VERSION ""

NS_ :

BS_:
BU_: VCU
BO_ 513 Motor: 3 VCU
   SG_ motor_mode : 0|8@1+ (1,0) [0|1] "" Vector__XXX
   SG_ torque_value : 8|16@1- (1,0) [0|1] "" Vector__XXX

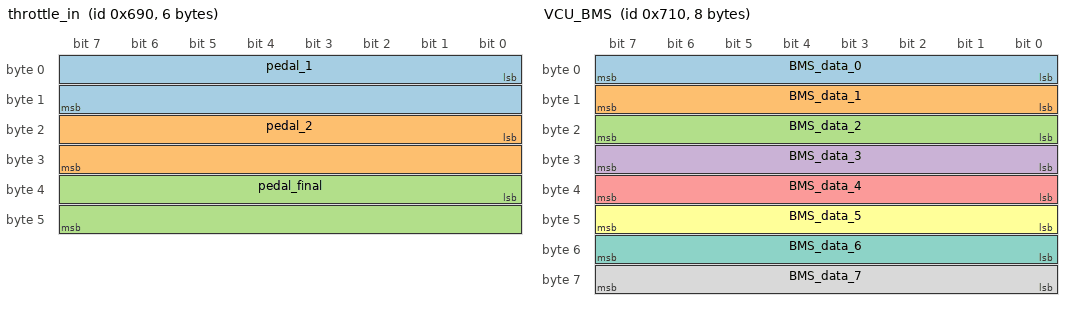
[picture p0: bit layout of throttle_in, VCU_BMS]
BO_ 1680 throttle_in: 6 VCU
   SG_ pedal_1 : 0|16@1+ (1,0) [0|1] "" Vector__XXX
   SG_ pedal_2 : 16|16@1+ (1,0) [0|1] "" Vector__XXX
   SG_ pedal_final : 32|16@1+ (1,0) [0|1] "" Vector__XXX

BO_ 1681 throttle_out: 6 VCU
   SG_ throttle_final : 0|16@1+ (1,0) [0|1] "" Vector__XXX
   SG_ throttle_torque_val : 16|16@1+ (1,0) [0|1] "" Vector__XXX

BO_ 1682 fault: 6 VCU
   SG_ fault_code : 0|8@1+ (1,0) [0|1] "" Vector__XXX
   SG_ delta : 8|32@5- (1,0) [0|1] "" Vector__XXX

BO_ 1683 car_status: 6 VCU
   SG_ car_status : 0|8@1+ (1,0) [0|1] "" Vector__XXX

BO_ 1792 TelemetryPedal: 8 VCU
   SG_ A01_APPS_5V : 0|10@1+ (1,0) [0|1] "" Vector__XXX
   SG_ A02_APPS_3V3 : 10|10@1+ (1,0) [0|1] "" Vector__XXX
   SG_ A03_BRAKE_IN : 20|10@1+ (1,0) [0|1] "" Vector__XXX
   SG_ A04_HALL_SENSOR : 30|10@1+ (1,0) [0|1] "" Vector__XXX
   SG_ B02_car_status_unknown : 42|1@0+ (1,0) [0|1] "" Vector__XXX
   SG_ B01_Car_state : 40|2@1+ (1,0) [0|3] "" Vector__XXX
   SG_ PedalFaultActive : 48|1@1+ (1,0) [0|255] "" Vector__XXX
   SG_ C00_Pedal_diff_fault_active : 48|1@1+ (1,0) [0|255] "" Vector__XXX
   SG_ B03_hv_on_ : 43|1@1+ (1,0) [0|1] "" Vector__XXX
   SG_ B04_read_no_message_ : 44|1@1+ (1,0) [0|1] "" Vector__XXX
   SG_ B05_read_wrong_id_ : 45|1@1+ (1,0) [0|1] "" Vector__XXX
   SG_ B06_throttle_break_ : 46|1@1+ (1,0) [0|1] "" Vector__XXX
   SG_ B07_forced_stop_ : 47|1@1+ (1,0) [0|1] "" Vector__XXX
   SG_ C01_fault_exceed_100ms : 49|1@1+ (1,0) [0|255] "" Vector__XXX
   SG_ C02_apps_5v_low : 50|1@1+ (1,0) [0|255] "" Vector__XXX
   SG_ C03_apps_5v_high : 51|1@1+ (1,0) [0|255] "" Vector__XXX
   SG_ C04_apps_3v3_low : 52|1@1+ (1,0) [0|255] "" Vector__XXX
   SG_ C05_apps_3v3_high : 53|1@1+ (1,0) [0|255] "" Vector__XXX
   SG_ C06_brake_low : 54|1@1+ (1,0) [0|255] "" Vector__XXX
   SG_ C07_brake_high : 55|1@1+ (1,0) [0|255] "" Vector__XXX

BO_ 1793 VCU_MOTOR: 8 VCU
   SG_ A01_TorqueVal : 0|16@1+ (1,0) [0|65535] "" Vector__XXX
   SG_ A02_MotorRPM : 16|16@1+ (0.183111,0) [0|6000] "rpm" Vector__XXX
   SG_ B00_error_bit0 : 32|1@0+ (1,0) [0|1] "" Vector__XXX
   SG_ B01_error_bit1 : 33|1@0+ (1,0) [0|1] "" Vector__XXX
   SG_ B02_error_bit2 : 34|1@0+ (1,0) [0|1] "" Vector__XXX
   SG_ B03_error_bit3 : 35|1@0+ (1,0) [0|1] "" Vector__XXX
   SG_ B04_error_bit4 : 36|1@0+ (1,0) [0|1] "" Vector__XXX
   SG_ B05_error_bit5 : 37|1@0+ (1,0) [0|1] "" Vector__XXX
   SG_ B06_error_bit6 : 38|1@0+ (1,0) [0|1] "" Vector__XXX
   SG_ B0_error_bit7 : 39|1@0+ (1,0) [0|1] "" Vector__XXX
   SG_ C00_warn_bit0 : 48|1@0+ (1,0) [0|1] "" Vector__XXX
   SG_ C01_warn_bit1 : 49|1@0+ (1,0) [0|1] "" Vector__XXX
   SG_ C02_warn_bit2 : 50|1@0+ (1,0) [0|1] "" Vector__XXX
   SG_ C03_warn_bit3 : 51|1@0+ (1,0) [0|1] "" Vector__XXX
   SG_ C04_warn_bit4 : 52|1@0+ (1,0) [0|1] "" Vector__XXX
   SG_ C05_warn_bit5 : 53|1@0+ (1,0) [0|1] "" Vector__XXX
   SG_ C06_warn_bit6 : 54|1@0+ (1,0) [0|1] "" Vector__XXX
   SG_ C07_warn_bit7 : 55|1@0+ (1,0) [0|1] "" Vector__XXX
   SG_ C08_warn_bit8 : 56|1@1+ (1,0) [0|1] "" Vector__XXX
   SG_ B08_error_bit8 : 40|1@0+ (1,0) [0|1] "" Vector__XXX
   SG_ B09_error_bit9 : 41|1@0+ (1,0) [0|1] "" Vector__XXX
   SG_ B10_error_bit10 : 42|1@0+ (1,0) [0|1] "" Vector__XXX
   SG_ B11_error_bit11 : 43|1@0+ (1,0) [0|1] "" Vector__XXX
   SG_ B12_error_bit12 : 44|1@0+ (1,0) [0|1] "" Vector__XXX
   SG_ B13_error_bit13 : 45|1@0+ (1,0) [0|1] "" Vector__XXX
   SG_ B14_error_bit14 : 46|1@0+ (1,0) [0|1] "" Vector__XXX
   SG_ B15_error_bit15 : 47|1@0+ (1,0) [0|1] "" Vector__XXX
   SG_ C09_warn_bit9 : 57|1@1+ (1,0) [0|1] "" Vector__XXX
   SG_ C10_warn_bit10 : 58|1@1+ (1,0) [0|1] "" Vector__XXX
   SG_ C11_warn_bit11 : 59|1@1+ (1,0) [0|1] "" Vector__XXX
   SG_ C12_warn_bit12 : 60|1@1+ (1,0) [0|1] "" Vector__XXX
   SG_ C13_warn_bit13 : 61|1@1+ (1,0) [0|1] "" Vector__XXX
   SG_ C14_warn_bit14 : 62|1@1+ (1,0) [0|1] "" Vector__XXX
   SG_ C15_warn_bit15 : 63|1@1+ (1,0) [0|1] "" Vector__XXX

BO_ 1808 VCU_BMS: 8 VCU
   SG_ BMS_data_0 : 0|8@1+ (1,0) [0|255] "" Vector__XXX
   SG_ BMS_data_1 : 8|8@1+ (1,0) [0|255] "" Vector__XXX
   SG_ BMS_data_2 : 16|8@1+ (1,0) [0|255] "" Vector__XXX
   SG_ BMS_data_3 : 24|8@1+ (1,0) [0|255] "" Vector__XXX
   SG_ BMS_data_4 : 32|8@1+ (1,0) [0|255] "" Vector__XXX
   SG_ BMS_data_5 : 40|8@1+ (1,0) [0|255] "" Vector__XXX
   SG_ BMS_data_6 : 48|8@1+ (1,0) [0|255] "" Vector__XXX
   SG_ BMS_data_7 : 56|8@1+ (1,0) [0|255] "" Vector__XXX

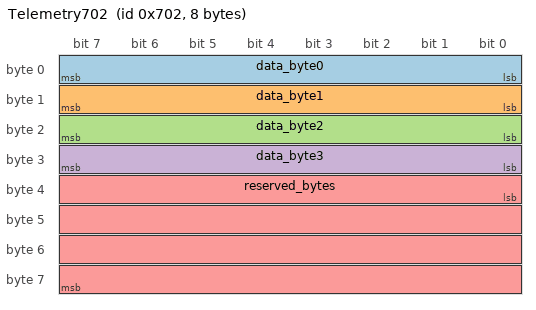
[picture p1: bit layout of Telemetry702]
BO_ 1794 Telemetry702: 8 VCU
   SG_ data_byte0 : 0|8@1+ (1,0) [0|255] "" Vector__XXX
   SG_ data_byte1 : 8|8@1+ (1,0) [0|255] "" Vector__XXX
   SG_ data_byte2 : 16|8@1+ (1,0) [0|255] "" Vector__XXX
   SG_ data_byte3 : 24|8@1+ (1,0) [0|255] "" Vector__XXX
   SG_ reserved_bytes : 32|32@1+ (1,0) [0|255] "" Vector__XXX

BA_DEF_ BO_ "GenMsgBackgroundColor" STRING ;
BA_DEF_ BO_ "GenMsgForegroundColor" STRING ;
BA_DEF_ BO_ "filterlabeling" INT 0 0;
BA_DEF_ BO_ "filterlabeling" INT 0 0;
BA_DEF_ BO_ "filterlabeling" INT 0 0;
BA_DEF_ BO_ "filterlabeling" INT 0 0;
BA_DEF_ BO_ "filterlabeling" INT 0 0;
BA_DEF_ BO_ "filterlabeling" INT 0 0;
BA_DEF_ BO_ "filterlabeling" INT 0 0;
BA_DEF_ BO_ "filterlabeling" INT 0 0;
BA_DEF_ BO_ "filterlabeling" INT 0 0;
BA_DEF_DEF_ "GenMsgBackgroundColor" "#ffffff";
BA_DEF_DEF_ "GenMsgForegroundColor" "#000000";
BA_DEF_DEF_ "filterlabeling" 1;
BA_DEF_DEF_ "filterlabeling" 1;
BA_ "GenMsgBackgroundColor" BO_ 513 "#a6ffff";
BA_ "GenMsgBackgroundColor" BO_ 1680 "#ffe9ca";
BA_ "GenMsgBackgroundColor" BO_ 1681 "#c6ffbc";
BA_ "GenMsgBackgroundColor" BO_ 1682 "#ff0000";
BA_ "GenMsgForegroundColor" BO_ 1682 "#c0fffa";
BA_ "GenMsgBackgroundColor" BO_ 1683 "#dfdeff";
BA_ "GenMsgBackgroundColor" BO_ 1792 "#ff8000";
BA_ "GenMsgBackgroundColor" BO_ 1793 "#73ff00";
VAL_ 513 motor_mode 144 "torque_command" 49 "No Description";
VAL_ 1682 fault_code 0 "No_fault" 1 "APPS_fault_started" 2 "APPS_fault_continuing" 3 "APPS_fault_exceeded_100ms" 4 "APPS_fault_resolved" 5 "APPS_too_low" 6 "APPS_too_high";
VAL_ 1683 car_status 0 "car_state_init" 1 "in_starting_sequence" 2 "buzzing" 3 "in_drive_mode";
VAL_ 1792 B02_car_status_unknown 0 "Inactive" 1 "Active";
VAL_ 1792 B01_Car_state 0 "Init" 1 "Startin" 2 "Bussin" 3 "Drive";
VAL_ 1792 PedalFaultActive 0 "Inactive" 1 "Active";
VAL_ 1792 C00_Pedal_diff_fault_active 0 "Inactive" 1 "Active";
VAL_ 1792 B03_hv_on_ 0 "Inactive";
VAL_ 1792 B04_read_no_message_ 0 "Inactive";
VAL_ 1792 B05_read_wrong_id_ 0 "Inactive";
VAL_ 1792 B06_throttle_break_ 0 "Inactive";
VAL_ 1792 B07_forced_stop_ 0 "Inactive";
VAL_ 1792 C01_fault_exceed_100ms 0 "Inactive" 1 "Active";
VAL_ 1792 C02_apps_5v_low 0 "Inactive" 1 "Active";
VAL_ 1792 C03_apps_5v_high 0 "Inactive" 1 "Active";
VAL_ 1792 C04_apps_3v3_low 0 "Inactive" 1 "Active";
VAL_ 1792 C05_apps_3v3_high 0 "Inactive" 1 "Active";
VAL_ 1792 C06_brake_low 0 "Inactive" 1 "Active";
VAL_ 1792 C07_brake_high 0 "Inactive" 1 "Active";
VAL_ 1793 B00_error_bit0 0 "inactive" 1 "active";
VAL_ 1793 B01_error_bit1 0 "inactive" 1 "active";
VAL_ 1793 B02_error_bit2 0 "Inactive" 1 "active";
